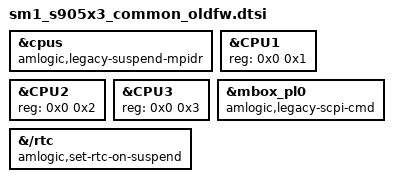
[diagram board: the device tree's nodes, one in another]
// SPDX-License-Identifier: (GPL-2.0+ OR MIT)
/*
 * S905X3 boxes that keep their stock Amlogic bootloader, with BL31
 * v1.3 4fc40b1 (May 2019), e.g. because secure boot locks it in.
 * sm1_s905x3_common.dtsi is written for the newer VIM3L firmware; this
 * file adapts it to the old one.
 */

#include "sm1_s905x3_common.dtsi"

/*
 * The old BL31 passes the PSCI CPU_ON target to the SCP as is, taking the
 * core from bits [3:0] and the cluster from [11:8], so the
 * 0x100/0x200/0x300 MPIDRs of mesonsm1.dtsi never power the cores on.
 * Use the core number in Aff0 like the stock 4.9 tree, which the newer
 * VIM3L BL31 accepts as well.
 *
 * CPU idle requires the kernel legacy-suspend-mpidr quirk to
 * match these CPU IDs when saving and restoring CPU context.
 */
&cpus {
	/* Match the legacy Aff0 CPU IDs below in the suspend context hash. */
	amlogic,legacy-suspend-mpidr;
};

&CPU1 {
	reg = <0x0 0x1>;
};

&CPU2 {
	reg = <0x0 0x2>;
};

&CPU3 {
	reg = <0x0 0x3>;
};

/*
 * The SCP firmware (BL30/BL301) of the same bootloader speaks the SCPI
 * protocol of the 4.9 kernel: the payload size goes in bits [28:20] of the
 * MHU command, which the old mailbox driver leaves out. It also only arms
 * the vrtc wakeup alarm after being given the time on suspend, as
 * scpi_set_vrtc() did in the 4.9 kernel.
 */
&mbox_pl0 {
	amlogic,legacy-scpi-cmd;
};

&{/rtc} {
	amlogic,set-rtc-on-suspend;
};

